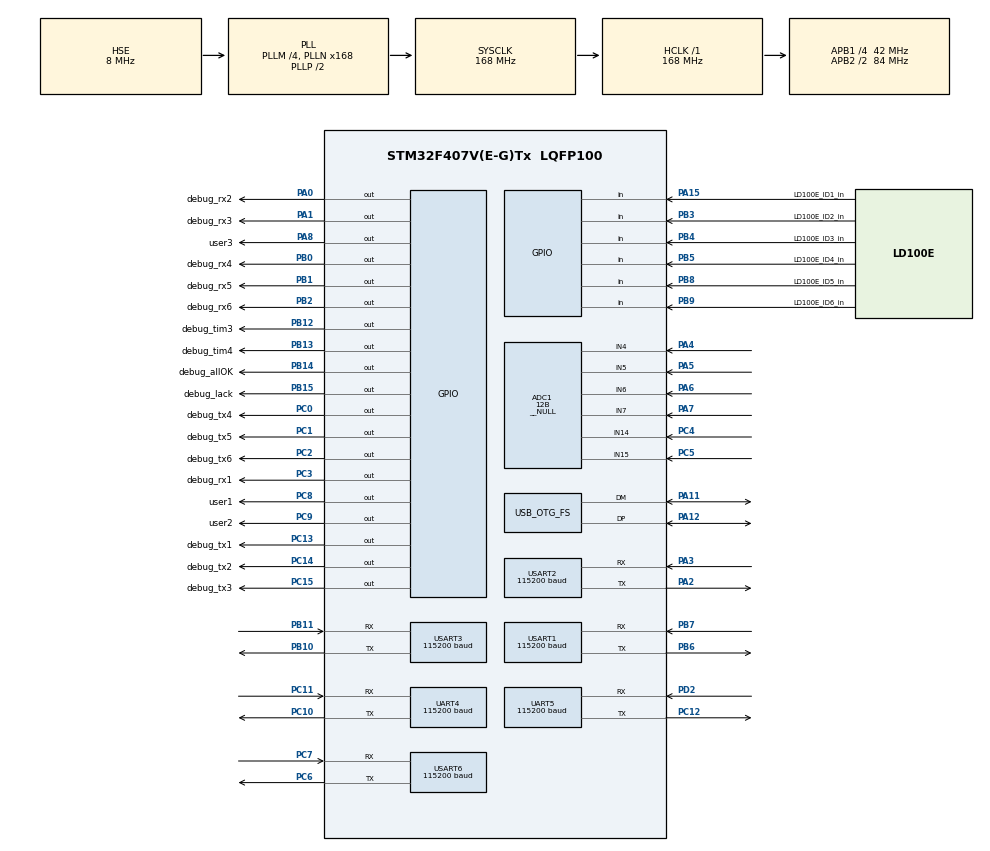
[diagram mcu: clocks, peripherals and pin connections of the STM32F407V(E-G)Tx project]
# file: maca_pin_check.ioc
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ADC1.Channel-0\#ChannelRegularConversion=ADC_CHANNEL_4
ADC1.Channel-IN14=ADC_CHANNEL_14
ADC1.Channel-IN15=ADC_CHANNEL_15
ADC1.Channel-IN4=ADC_CHANNEL_4
ADC1.Channel-IN5=ADC_CHANNEL_5
ADC1.Channel-IN6=ADC_CHANNEL_6
ADC1.Channel-IN7=ADC_CHANNEL_7
ADC1.ClockPrescaler=ADC_CLOCK_SYNC_PCLK_DIV4
ADC1.ContinuousConvMode=ENABLE
ADC1.DMAContinuousRequests=DISABLE
ADC1.DataAlign=ADC_DATAALIGN_RIGHT
ADC1.DiscontinuousConvMode=DISABLE
ADC1.EOCSelection=ADC_EOC_SINGLE_CONV
ADC1.EnableAnalogWatchDog=false
ADC1.ExternalTrigConv=ADC_SOFTWARE_START
ADC1.ExternalTrigConvEdge=ADC_EXTERNALTRIGCONVEDGE_NONE
ADC1.InjNumberOfConversion=0
ADC1.Mode=__NULL
ADC1.NbrOfConversion=1
ADC1.Rank-0\#ChannelRegularConversion=1
ADC1.Resolution=ADC_RESOLUTION_12B
ADC1.SamplingTime-0\#ChannelRegularConversion=ADC_SAMPLETIME_3CYCLES
ADC1.ScanConvMode=DISABLE
ADC1.master=1
Dma.Request0=USART1_RX
Dma.Request1=UART4_RX
Dma.Request2=UART5_RX
Dma.Request3=USART2_RX
Dma.Request4=USART3_RX
Dma.Request5=USART6_RX
Dma.UART4_RX.1.Direction=DMA_PERIPH_TO_MEMORY
Dma.UART4_RX.1.FIFOMode=DMA_FIFOMODE_DISABLE
Dma.UART4_RX.1.Instance=DMA1_Stream2
Dma.UART4_RX.1.MemDataAlignment=DMA_MDATAALIGN_BYTE
Dma.UART4_RX.1.MemInc=DMA_MINC_ENABLE
Dma.UART4_RX.1.Mode=DMA_NORMAL
Dma.UART4_RX.1.PeriphDataAlignment=DMA_PDATAALIGN_BYTE
Dma.UART4_RX.1.PeriphInc=DMA_PINC_DISABLE
Dma.UART4_RX.1.Priority=DMA_PRIORITY_HIGH
Dma.UART5_RX.2.Direction=DMA_PERIPH_TO_MEMORY
Dma.UART5_RX.2.FIFOMode=DMA_FIFOMODE_DISABLE
Dma.UART5_RX.2.Instance=DMA1_Stream0
Dma.UART5_RX.2.MemDataAlignment=DMA_MDATAALIGN_BYTE
Dma.UART5_RX.2.MemInc=DMA_MINC_ENABLE
Dma.UART5_RX.2.Mode=DMA_NORMAL
Dma.UART5_RX.2.PeriphDataAlignment=DMA_PDATAALIGN_BYTE
Dma.UART5_RX.2.PeriphInc=DMA_PINC_DISABLE
Dma.UART5_RX.2.Priority=DMA_PRIORITY_HIGH
Dma.USART1_RX.0.Direction=DMA_PERIPH_TO_MEMORY
Dma.USART1_RX.0.FIFOMode=DMA_FIFOMODE_DISABLE
Dma.USART1_RX.0.Instance=DMA2_Stream2
Dma.USART1_RX.0.MemDataAlignment=DMA_MDATAALIGN_BYTE
Dma.USART1_RX.0.MemInc=DMA_MINC_ENABLE
Dma.USART1_RX.0.Mode=DMA_NORMAL
Dma.USART1_RX.0.PeriphDataAlignment=DMA_PDATAALIGN_BYTE
Dma.USART1_RX.0.PeriphInc=DMA_PINC_DISABLE
Dma.USART1_RX.0.Priority=DMA_PRIORITY_HIGH
Dma.USART2_RX.3.Direction=DMA_PERIPH_TO_MEMORY
Dma.USART2_RX.3.FIFOMode=DMA_FIFOMODE_DISABLE
Dma.USART2_RX.3.Instance=DMA1_Stream5
Dma.USART2_RX.3.MemDataAlignment=DMA_MDATAALIGN_BYTE
Dma.USART2_RX.3.MemInc=DMA_MINC_ENABLE
Dma.USART2_RX.3.Mode=DMA_NORMAL
Dma.USART2_RX.3.PeriphDataAlignment=DMA_PDATAALIGN_BYTE
Dma.USART2_RX.3.PeriphInc=DMA_PINC_DISABLE
Dma.USART2_RX.3.Priority=DMA_PRIORITY_HIGH
Dma.USART3_RX.4.Direction=DMA_PERIPH_TO_MEMORY
Dma.USART3_RX.4.FIFOMode=DMA_FIFOMODE_DISABLE
Dma.USART3_RX.4.Instance=DMA1_Stream1
Dma.USART3_RX.4.MemDataAlignment=DMA_MDATAALIGN_BYTE
Dma.USART3_RX.4.MemInc=DMA_MINC_ENABLE
Dma.USART3_RX.4.Mode=DMA_NORMAL
Dma.USART3_RX.4.PeriphDataAlignment=DMA_PDATAALIGN_BYTE
Dma.USART3_RX.4.PeriphInc=DMA_PINC_DISABLE
Dma.USART3_RX.4.Priority=DMA_PRIORITY_HIGH
Dma.USART6_RX.5.Direction=DMA_PERIPH_TO_MEMORY
Dma.USART6_RX.5.FIFOMode=DMA_FIFOMODE_DISABLE
Dma.USART6_RX.5.Instance=DMA2_Stream1
Dma.USART6_RX.5.MemDataAlignment=DMA_MDATAALIGN_BYTE
Dma.USART6_RX.5.MemInc=DMA_MINC_ENABLE
Dma.USART6_RX.5.Mode=DMA_NORMAL
Dma.USART6_RX.5.PeriphDataAlignment=DMA_PDATAALIGN_BYTE
Dma.USART6_RX.5.PeriphInc=DMA_PINC_DISABLE
Dma.USART6_RX.5.Priority=DMA_PRIORITY_HIGH
Mcu.Family=STM32F4
Mcu.Name=STM32F407V(E-G)Tx
Mcu.Package=LQFP100
NVIC.DMA1_Stream0_IRQn=true\:5\:0\:true\:false\:true\:false\:true\:true
NVIC.DMA1_Stream1_IRQn=true\:5\:0\:true\:false\:true\:false\:true\:true
NVIC.DMA1_Stream2_IRQn=true\:5\:0\:true\:false\:true\:false\:true\:true
NVIC.DMA1_Stream5_IRQn=true\:5\:0\:true\:false\:true\:false\:true\:true
NVIC.DMA2_Stream1_IRQn=true\:5\:0\:true\:false\:true\:true\:true\:true
NVIC.DMA2_Stream2_IRQn=true\:0\:0\:false\:false\:true\:false\:true\:true
NVIC.OTG_FS_IRQn=true\:1\:0\:true\:false\:true\:false\:true\:true
NVIC.PriorityGroup=NVIC_PRIORITYGROUP_4
NVIC.TIM3_IRQn=true\:14\:0\:true\:false\:true\:true\:true\:true
NVIC.TIM4_IRQn=true\:13\:0\:true\:false\:true\:true\:true\:true
NVIC.UART4_IRQn=true\:4\:0\:true\:false\:true\:true\:true\:true
NVIC.UART5_IRQn=true\:4\:0\:true\:false\:true\:true\:true\:true
NVIC.USART1_IRQn=true\:4\:0\:true\:false\:true\:true\:true\:true
NVIC.USART2_IRQn=true\:4\:0\:true\:false\:true\:true\:true\:true
NVIC.USART3_IRQn=true\:4\:0\:true\:false\:true\:true\:true\:true
NVIC.USART6_IRQn=true\:4\:0\:true\:false\:true\:true\:true\:true
PA0-WKUP.GPIO_Label=debug_rx2
PA0-WKUP.GPIO_PuPd=GPIO_PULLDOWN
PA0-WKUP.GPIO_Speed=GPIO_SPEED_FREQ_HIGH
PA0-WKUP.Signal=GPIO_Output
PA1.GPIO_Label=debug_rx3
PA1.GPIO_PuPd=GPIO_PULLDOWN
PA1.GPIO_Speed=GPIO_SPEED_FREQ_HIGH
PA1.Signal=GPIO_Output
PA10.Signal=USB_OTG_FS_ID
PA11.Mode=Device_Only
PA11.Signal=USB_OTG_FS_DM
PA12.Mode=Device_Only
PA12.Signal=USB_OTG_FS_DP
PA13.Mode=Serial_Wire
PA13.Signal=SYS_JTMS-SWDIO
PA14.Mode=Serial_Wire
PA14.Signal=SYS_JTCK-SWCLK
PA15.GPIO_Label=LD100E_ID1_in
PA15.GPIO_PuPd=GPIO_PULLDOWN
PA15.Signal=GPIO_Input
PA2.Mode=Asynchronous
PA2.Signal=USART2_TX
PA3.Mode=Asynchronous
PA3.Signal=USART2_RX
PA4.Signal=ADCx_IN4
PA5.Signal=ADCx_IN5
PA6.Signal=ADCx_IN6
PA7.Signal=ADCx_IN7
PA8.GPIO_Label=user3
PA8.Signal=GPIO_Output
PA9.Signal=USB_OTG_FS_VBUS
PB0.GPIO_Label=debug_rx4
PB0.GPIO_PuPd=GPIO_PULLDOWN
PB0.GPIO_Speed=GPIO_SPEED_FREQ_HIGH
PB0.Signal=GPIO_Output
PB1.GPIO_Label=debug_rx5
PB1.GPIO_PuPd=GPIO_PULLDOWN
PB1.GPIO_Speed=GPIO_SPEED_FREQ_HIGH
PB1.Signal=GPIO_Output
PB10.Mode=Asynchronous
PB10.Signal=USART3_TX
PB11.Mode=Asynchronous
PB11.Signal=USART3_RX
PB12.GPIO_Label=debug_tim3
PB12.GPIO_PuPd=GPIO_PULLDOWN
PB12.GPIO_Speed=GPIO_SPEED_FREQ_HIGH
PB12.Signal=GPIO_Output
PB13.GPIO_Label=debug_tim4
PB13.GPIO_PuPd=GPIO_PULLDOWN
PB13.GPIO_Speed=GPIO_SPEED_FREQ_HIGH
PB13.Signal=GPIO_Output
PB14.GPIO_Label=debug_allOK
PB14.GPIO_PuPd=GPIO_PULLDOWN
PB14.GPIO_Speed=GPIO_SPEED_FREQ_HIGH
PB14.Signal=GPIO_Output
PB15.GPIO_Label=debug_lack
PB15.GPIO_PuPd=GPIO_PULLDOWN
PB15.GPIO_Speed=GPIO_SPEED_FREQ_HIGH
PB15.Signal=GPIO_Output
PB2.GPIO_Label=debug_rx6
PB2.GPIO_PuPd=GPIO_PULLDOWN
PB2.GPIO_Speed=GPIO_SPEED_FREQ_HIGH
PB2.Signal=GPIO_Output
PB3.GPIO_Label=LD100E_ID2_in
PB3.GPIO_PuPd=GPIO_PULLDOWN
PB3.Signal=GPIO_Input
PB4.GPIO_Label=LD100E_ID3_in
PB4.GPIO_PuPd=GPIO_PULLDOWN
PB4.Signal=GPIO_Input
PB5.GPIO_Label=LD100E_ID4_in
PB5.GPIO_PuPd=GPIO_PULLDOWN
PB5.Signal=GPIO_Input
PB6.Mode=Asynchronous
PB6.Signal=USART1_TX
PB7.Mode=Asynchronous
PB7.Signal=USART1_RX
PB8.GPIO_Label=LD100E_ID5_in
PB8.GPIO_PuPd=GPIO_PULLDOWN
PB8.Signal=GPIO_Input
PB9.GPIO_Label=LD100E_ID6_in
PB9.GPIO_PuPd=GPIO_PULLDOWN
PB9.Signal=GPIO_Input
PC0.GPIO_Label=debug_tx4
PC0.GPIO_PuPd=GPIO_PULLDOWN
PC0.GPIO_Speed=GPIO_SPEED_FREQ_HIGH
PC0.Signal=GPIO_Output
PC1.GPIO_Label=debug_tx5
PC1.GPIO_PuPd=GPIO_PULLDOWN
PC1.GPIO_Speed=GPIO_SPEED_FREQ_HIGH
PC1.Signal=GPIO_Output
PC10.Mode=Asynchronous
PC10.Signal=UART4_TX
PC11.Mode=Asynchronous
PC11.Signal=UART4_RX
PC12.Mode=Asynchronous
PC12.Signal=UART5_TX
PC13-ANTI_TAMP.GPIO_Label=debug_tx1
PC13-ANTI_TAMP.GPIO_PuPd=GPIO_PULLDOWN
PC13-ANTI_TAMP.Signal=GPIO_Output
PC14-OSC32_IN.GPIO_Label=debug_tx2
PC14-OSC32_IN.GPIO_PuPd=GPIO_PULLDOWN
PC14-OSC32_IN.Signal=GPIO_Output
PC15-OSC32_OUT.GPIO_Label=debug_tx3
PC15-OSC32_OUT.GPIO_PuPd=GPIO_PULLDOWN
PC15-OSC32_OUT.Signal=GPIO_Output
PC2.GPIO_Label=debug_tx6
PC2.GPIO_PuPd=GPIO_PULLDOWN
PC2.GPIO_Speed=GPIO_SPEED_FREQ_HIGH
PC2.Signal=GPIO_Output
PC3.GPIO_Label=debug_rx1
PC3.GPIO_PuPd=GPIO_PULLDOWN
PC3.GPIO_Speed=GPIO_SPEED_FREQ_HIGH
PC3.Signal=GPIO_Output
PC4.Signal=ADCx_IN14
PC5.Signal=ADCx_IN15
PC6.Mode=Asynchronous
PC6.Signal=USART6_TX
PC7.Mode=Asynchronous
PC7.Signal=USART6_RX
PC8.GPIO_Label=user1
PC8.Signal=GPIO_Output
PC9.GPIO_Label=user2
PC9.Signal=GPIO_Output
PD2.Mode=Asynchronous
PD2.Signal=UART5_RX
PH0-OSC_IN.Mode=HSE-External-Oscillator
PH0-OSC_IN.Signal=RCC_OSC_IN
PH1-OSC_OUT.Mode=HSE-External-Oscillator
PH1-OSC_OUT.Signal=RCC_OSC_OUT
ProjectManager.HeapSize=0x200
ProjectManager.StackSize=0x400
ProjectManager.TargetToolchain=Makefile
RCC.48MHZClocksFreq_Value=48000000
RCC.AHBFreq_Value=168000000
RCC.APB1CLKDivider=RCC_HCLK_DIV4
RCC.APB1Freq_Value=42000000
RCC.APB1TimFreq_Value=84000000
RCC.APB2CLKDivider=RCC_HCLK_DIV2
RCC.APB2Freq_Value=84000000
RCC.APB2TimCLKDivider=2
RCC.APB2TimFreq_Value=168000000
RCC.CortexFreq_Value=168000000
RCC.HCLKFreq_Value=168000000
RCC.HSE_VALUE=8000000
RCC.HSI_VALUE=16000000
RCC.LSE_VALUE=32768
RCC.PLLM=4
RCC.PLLN=168
RCC.PLLQ=7
RCC.SYSCLKFreq_VALUE=168000000
RCC.SYSCLKSource=RCC_SYSCLKSOURCE_PLLCLK
RCC.VCOOutputFreq_Value=336000000
SH.ADCx_IN14.0=ADC1_IN14,IN14
SH.ADCx_IN15.0=ADC1_IN15,IN15
SH.ADCx_IN4.0=ADC1_IN4,IN4
SH.ADCx_IN5.0=ADC1_IN5,IN5
SH.ADCx_IN6.0=ADC1_IN6,IN6
SH.ADCx_IN7.0=ADC1_IN7,IN7
TIM3.AutoReloadPreload=TIM_AUTORELOAD_PRELOAD_ENABLE
TIM3.Period=4999
TIM3.Prescaler=83
TIM4.AutoReloadPreload=TIM_AUTORELOAD_PRELOAD_ENABLE
TIM4.Period=99
TIM4.Prescaler=83
UART4.BaudRate=115200
UART4.Mode=MODE_TX_RX
UART4.OverSampling=UART_OVERSAMPLING_16
UART4.Parity=PARITY_NONE
UART4.StopBits=UART_STOPBITS_1
UART4.VirtualMode=Asynchronous
UART4.WordLength=WORDLENGTH_8B
UART5.BaudRate=115200
UART5.Mode=MODE_TX_RX
UART5.OverSampling=UART_OVERSAMPLING_16
UART5.Parity=PARITY_NONE
UART5.StopBits=UART_STOPBITS_1
UART5.VirtualMode=Asynchronous
UART5.WordLength=WORDLENGTH_8B
USART1.BaudRate=115200
USART1.Mode=MODE_TX_RX
USART1.OverSampling=UART_OVERSAMPLING_16
USART1.Parity=PARITY_NONE
USART1.StopBits=STOPBITS_1
USART1.VirtualMode=VM_ASYNC
USART1.WordLength=WORDLENGTH_8B
USART2.BaudRate=115200
USART2.Mode=MODE_TX_RX
USART2.OverSampling=UART_OVERSAMPLING_16
USART2.Parity=PARITY_NONE
USART2.StopBits=STOPBITS_1
USART2.VirtualMode=VM_ASYNC
USART2.WordLength=WORDLENGTH_8B
USART3.BaudRate=115200
USART3.Mode=MODE_TX_RX
USART3.OverSampling=UART_OVERSAMPLING_16
USART3.Parity=PARITY_NONE
USART3.StopBits=STOPBITS_1
USART3.VirtualMode=VM_ASYNC
USART3.WordLength=WORDLENGTH_8B
USART6.BaudRate=115200
USART6.Mode=MODE_TX_RX
USART6.OverSampling=UART_OVERSAMPLING_16
USART6.Parity=PARITY_NONE
USART6.StopBits=STOPBITS_1
USART6.VirtualMode=VM_ASYNC
USART6.WordLength=WORDLENGTH_8B
USB_DEVICE.CLASS_NAME_FS=CDC
USB_DEVICE.VirtualMode-CDC_FS=Cdc
USB_DEVICE.VirtualModeFS=Cdc_FS
USB_OTG_FS.VirtualMode=Device_Only
VP_TIM3_VS_ClockSourceINT.Mode=Internal
VP_TIM4_VS_ClockSourceINT.Mode=Internal
VP_USB_DEVICE_VS_USB_DEVICE_CDC_FS.Mode=CDC_FS
board=custom

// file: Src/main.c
/* USER CODE BEGIN Header */
/**
	******************************************************************************
	* @file           : main.c
	* @brief          : Main program body
	******************************************************************************
	* @attention
	*
	* Copyright (c) 2024 STMicroelectronics.
	* All rights reserved.
	*
	* This software is licensed under terms that can be found in the LICENSE file
	* in the root directory of this software component.
	* If no LICENSE file comes with this software, it is provided AS-IS.
	*
	******************************************************************************
	*/
/* USER CODE END Header */
#include "main.h"
#include "adc.h"
#include "dma.h"
#include "tim.h"
#include "usart.h"
#include "usb_device.h"
#include "gpio.h"

/* USER CODE BEGIN Includes */
#include "usbd_cdc_if.h"
#include "cas_macaps15.h"
/* USER CODE END Includes */

/* USER CODE BEGIN PV */
int delay_time_1ms;
/* USER CODE END PV */

void SystemClock_Config(void);

int main(void)
{

	/* MCU Configuration--------------------------------------------------------*/

	/* Reset of all peripherals, Initializes the Flash interface and the Systick. */
	HAL_Init();

	/* Configure the system clock */
	SystemClock_Config();

	/* Initialize all configured peripherals */
	MX_GPIO_Init();
	MX_DMA_Init();
	MX_ADC1_Init();
	MX_UART4_Init();
	MX_UART5_Init();
	MX_USART1_UART_Init();
	MX_USART2_UART_Init();
	MX_USART3_UART_Init();
	MX_USART6_UART_Init();
	MX_TIM3_Init();
	MX_USB_DEVICE_Init();
	MX_TIM4_Init();
	/* USER CODE BEGIN 2 */
	HAL_TIM_Base_Start_IT(&htim3);

	/* USER CODE END 2 */

	/* Infinite loop */
	while (1)
	{

		/* USER CODE BEGIN 3 */
		// for(int for_tim4=0; for_tim4<number_of_legs; for_tim4++)
		// {
		// 	CDC_Transmit_FS(&for_tim4,1);
		// 	delay_1ms(1);
		// }
	}
	/* USER CODE END 3 */
}

void SystemClock_Config(void)
{
	RCC_OscInitTypeDef RCC_OscInitStruct = {0};
	RCC_ClkInitTypeDef RCC_ClkInitStruct = {0};

	/** Configure the main internal regulator output voltage
	*/
	__HAL_RCC_PWR_CLK_ENABLE();
	__HAL_PWR_VOLTAGESCALING_CONFIG(PWR_REGULATOR_VOLTAGE_SCALE1);

	/** Initializes the RCC Oscillators according to the specified parameters
	* in the RCC_OscInitTypeDef structure.
	*/
	RCC_OscInitStruct.OscillatorType = RCC_OSCILLATORTYPE_HSE;
	RCC_OscInitStruct.HSEState = RCC_HSE_ON;
	RCC_OscInitStruct.PLL.PLLState = RCC_PLL_ON;
	RCC_OscInitStruct.PLL.PLLSource = RCC_PLLSOURCE_HSE;
	RCC_OscInitStruct.PLL.PLLM = 4;
	RCC_OscInitStruct.PLL.PLLN = 168;
	RCC_OscInitStruct.PLL.PLLP = RCC_PLLP_DIV2;
	RCC_OscInitStruct.PLL.PLLQ = 7;
	if (HAL_RCC_OscConfig(&RCC_OscInitStruct) != HAL_OK)
	{
		Error_Handler();
	}

	/** Initializes the CPU, AHB and APB buses clocks
	*/
	RCC_ClkInitStruct.ClockType = RCC_CLOCKTYPE_HCLK|RCC_CLOCKTYPE_SYSCLK
								 |RCC_CLOCKTYPE_PCLK1|RCC_CLOCKTYPE_PCLK2;
	RCC_ClkInitStruct.SYSCLKSource = RCC_SYSCLKSOURCE_PLLCLK;
	RCC_ClkInitStruct.AHBCLKDivider = RCC_SYSCLK_DIV1;
	RCC_ClkInitStruct.APB1CLKDivider = RCC_HCLK_DIV4;
	RCC_ClkInitStruct.APB2CLKDivider = RCC_HCLK_DIV2;

	if (HAL_RCC_ClockConfig(&RCC_ClkInitStruct, FLASH_LATENCY_5) != HAL_OK)
	{
		Error_Handler();
	}
}

/* USER CODE BEGIN 4 */

/**
	 * @brief delay 1ms
	* @param t delay time, unit:1ms
	* @retval None
*/
void delay_1ms(int t)
{
	delay_time_1ms = t;
	while(delay_time_1ms>0){}
}

/* USER CODE END 4 */

void Error_Handler(void)
{
	__disable_irq();
	while (1)
	{
	}
}
